# S6E2GMxH register map
Vendor: Cypress; File version: 2.1
CPU: CM4 r0p1, little endian, MPU, FPU, 4 interrupt priority bits
Registers are 32-bit, read-write, reset 0x0 unless marked. A register's access mark holds for its fields unless they carry their own. Offsets are from the block's base; [hi:lo] are bit positions; {n}, {i} and the like mark numbered series.

## USB0 — USB0 Function
Base 0x40040000
Same registers: USB1 0x40052100
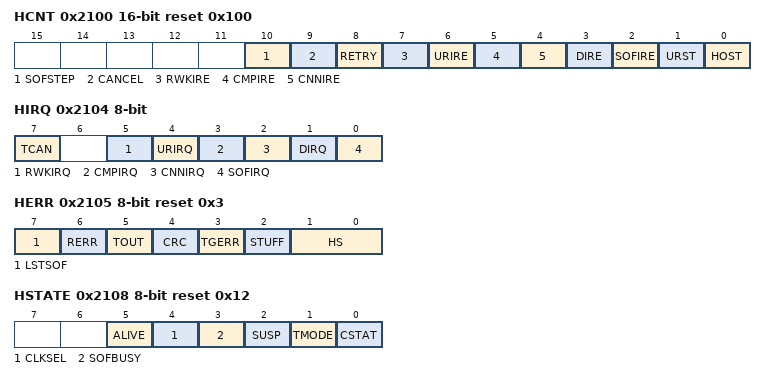
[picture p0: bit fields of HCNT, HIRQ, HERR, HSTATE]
0x2100 HCNT 16-bit reset 0x100 — Host Control Register [BHW]
  [10] SOFSTEP — SOF interrupt occurrence selection bit
  [9] CANCEL — token cancellation enable bit
  [8] RETRY — retry enable bit
  [7] RWKIRE — resume interrupt enable bit
  [6] URIRE — bus reset interrupt enable bit
  [5] CMPIRE — token completion interrupt enable bit
  [4] CNNIRE — device connection detection interrupt enable bit
  [3] DIRE — device disconnection detection interrupt enable bit
  [2] SOFIRE — SOF interrupt enable bit
  [1] URST — bus reset bit
  [0] HOST — host mode bit
0x2104 HIRQ 8-bit — Host Interrupt Register [BHW]
  [7] TCAN — token cancellation flag
  [5] RWKIRQ — remote Wake-up end flag
  [4] URIRQ — bus reset end flag
  [3] CMPIRQ — token completion flag
  [2] CNNIRQ — device connection detection flag
  [1] DIRQ — device disconnection detection flag
  [0] SOFIRQ — SOF starting flag
0x2105 HERR 8-bit reset 0x3 — Host Error Status Register [BHW]
  [7] LSTSOF — lost SOF flag
  [6] RERR — receive error flag
  [5] TOUT — timeout flag
  [4] CRC — CRC error flag
  [3] TGERR — toggle error flag
  [2] STUFF — stuffing error flag
  [1:0] HS — handshake status flags
0x2108 HSTATE 8-bit reset 0x12 — Host Status Register [BHW]
  [5] ALIVE — specify the keep-alive function in the low-speed mode
  [4] CLKSEL — USB operation clock selection bit
  [3] SOFBUSY — SOF busy flag
  [2] SUSP — suspend setting bit
  [1] TMODE ro — transmission mode flag
  [0] CSTAT ro — connection status flag
0x2109 HFCOMP 8-bit — SOF Interrupt Frame Compare Register [BHW]
  [7:0] FRAMECOMP — frame compare data
0x210C HRTIMER 16-bit — Retry Timer Setup Register [BHW]
  [15:0] RTIMER — retry timer setting
0x2110 HRTIMER2 8-bit — Retry Timer Setup Register 2 [BHW]
  [1:0] RTIMER2 — retry timer setting 2
0x2111 HADR 8-bit — Host Address Register [BHW]
  [6:0] ADDRESS — Host Address
0x2114 HEOF 16-bit — EOF Setup Register [BHW]
  [13:0] HEOF — End Frame
0x2118 HFRAME 16-bit — Frame Setup Register [BHW]
  [10:0] FRAME — Frame Setup
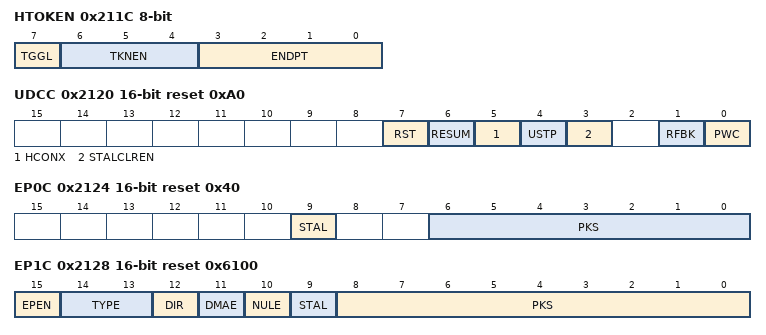
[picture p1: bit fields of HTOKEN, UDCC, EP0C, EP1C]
0x211C HTOKEN 8-bit — Host Token Endpoint Register [BHW]
  [7] TGGL — toggle bit
  [6:4] TKNEN — token enable bits
  [3:0] ENDPT — endpoint bits
0x2120 UDCC 16-bit reset 0xA0 — UDC Control Register [BHW]
  [7] RST — Function Reset bit
  [6] RESUM — Resume Setting bit
  [5] HCONX — Host Connection bit
  [4] USTP — USB Operating Clock Stop bit
  [3] STALCLREN — Endpoint 1 to 5 STAL bit Clear Select bit
  [1] RFBK — Data Toggle Mode Select bit
  [0] PWC — Power Control bit
0x2124 EP0C 16-bit reset 0x40 — EP0 Control Register [HW]
  [9] STAL — Endpoint 0 Stall Setting bit
  [6:0] PKS — Packet Size Endpoint 0 Setting bits
0x2128 EP1C 16-bit reset 0x6100 — EP1 Control Register [HW]
  [15] EPEN — Endpoint Enable bit
  [14:13] TYPE — Endpoint Transfer Type Select bits
  [12] DIR — Endpoint Transfer Direction Select bit
  [11] DMAE — DMA Automatic Transfer Enable bit
  [10] NULE — Null Automatic Transfer Enable bit
  [9] STAL — Endpoint Stall Setting bit
  [8:0] PKS — Packet Size Setting bits
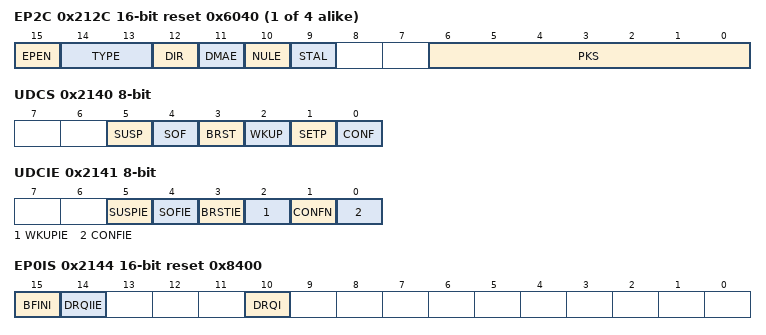
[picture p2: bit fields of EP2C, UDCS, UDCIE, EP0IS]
{0x2124+4i} EP{i}C 16-bit reset 0x6040 (i=2..5) — EP{i} Control Register [HW]
  [15] EPEN — Endpoint Enable bit
  [14:13] TYPE — Endpoint Transfer Type Select bits
  [12] DIR — Endpoint Transfer Direction Select bit
  [11] DMAE — DMA Automatic Transfer Enable bit
  [10] NULE — Null Automatic Transfer Enable bit
  [9] STAL — Endpoint Stall Setting bit
  [6:0] PKS — Packet Size Setting bits
0x213C TMSP 16-bit ro — Time Stamp Register [HW]
  [10:0] TMSP — Time Stamp bits
0x2140 UDCS 8-bit — UDC Status Register [BHW]
  [5] SUSP — Suspend detection bit
  [4] SOF — SOF Detection bit
  [3] BRST — Bus Reset Detection bit
  [2] WKUP — Wake-up Detection bit
  [1] SETP — Setup Stage Detection bit
  [0] CONF — Configuration Detection bit
0x2141 UDCIE 8-bit — UDC Interrupt Enable Register [BHW]
  [5] SUSPIE — Suspend Interrupt Enable bit
  [4] SOFIE — SOF Reception Interrupt Enable bit
  [3] BRSTIE — Bus Reset Enable bit
  [2] WKUPIE — Wake-up Interrupt Enable bit
  [1] CONFN ro — Configuration Number Indication bit
  [0] CONFIE — Configuration Interrupt Enable bit
0x2144 EP0IS 16-bit reset 0x8400 — EP0I Status Register [HW]
  [15] BFINI — Send Buffer Initialization bit
  [14] DRQIIE — Send Data Interrupt Enable bit
  [10] DRQI — Send/Receive Data Interrupt Request bit
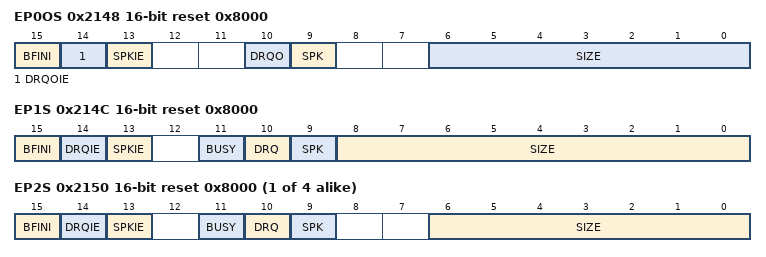
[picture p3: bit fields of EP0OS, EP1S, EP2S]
0x2148 EP0OS 16-bit reset 0x8000 (reset mask 0xE600) — EP0O Status Register [HW]
  [15] BFINI — Receive Buffer Initialization bit
  [14] DRQOIE — Receive Data Interrupt Enable bit
  [13] SPKIE — Short Packet Interrupt Enable bit
  [10] DRQO — Receive Data Interrupt Request bit
  [9] SPK — Short Packet Interrupt Request bit
  [6:0] SIZE ro — Packet Size Indication bit
0x214C EP1S 16-bit reset 0x8000 (reset mask 0xEF00) — EP1 Status Register [HW]
  [15] BFINI — Send/Receive Buffer Initialization bit
  [14] DRQIE — Packet Transfer Interrupt Enable bit
  [13] SPKIE — Short Packet Interrupt Enable bit
  [11] BUSY ro — Busy Flag bit
  [10] DRQ — Packet Transfer Interrupt Request bit
  [9] SPK — Short Packet Interrupt Request bit
  [8:0] SIZE ro — packet SIZE
{0x2148+4i} EP{i}S 16-bit reset 0x8000 (reset mask 0xEE80) (i=2..5) — EP{i} Status Register [HW]
  [15] BFINI — Send/Receive Buffer Initialization bit
  [14] DRQIE — Packet Transfer Interrupt Enable bit
  [13] SPKIE — Short Packet Interrupt Enable bit
  [11] BUSY ro — Busy Flag bit
  [10] DRQ — Packet Transfer Interrupt Request bit
  [9] SPK — Short Packet Interrupt Request bit
  [6:0] SIZE ro — packet SIZE
{0x2160+4i} EP{i}DT 16-bit reset not defined (i=0..5) — EP{i} Data Register [BHW]
  [15:0] BFDT — Endpoint Send/Receive Buffer Data
